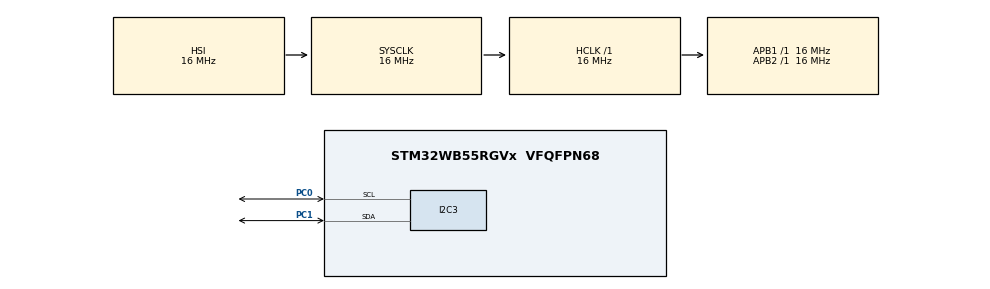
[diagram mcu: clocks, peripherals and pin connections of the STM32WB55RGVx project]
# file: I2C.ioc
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I2C3.Timing=0x00303D5B
Mcu.Family=STM32WB
Mcu.Name=STM32WB55RGVx
Mcu.Package=VFQFPN68
NVIC.PriorityGroup=NVIC_PRIORITYGROUP_4
PC0.GPIO_Pu=GPIO_PULLUP
PC0.GPIO_Speed=GPIO_SPEED_FREQ_HIGH
PC0.Mode=I2C
PC0.Signal=I2C3_SCL
PC1.GPIO_Pu=GPIO_PULLUP
PC1.GPIO_Speed=GPIO_SPEED_FREQ_HIGH
PC1.Mode=I2C
PC1.Signal=I2C3_SDA
ProjectManager.HeapSize=0x200
ProjectManager.StackSize=0x400
ProjectManager.TargetToolchain=STM32CubeIDE
RCC.ADCFreq_Value=64000000
RCC.AHBFreq_Value=16000000
RCC.APB1Freq_Value=16000000
RCC.APB1TimFreq_Value=16000000
RCC.APB2Freq_Value=16000000
RCC.APB2TimFreq_Value=16000000
RCC.APB3Freq_Value=16000000
RCC.CortexFreq_Value=16000000
RCC.HCLKFreq_Value=16000000
RCC.HSE_VALUE=8000000
RCC.HSI48_VALUE=48000000
RCC.HSI_VALUE=16000000
RCC.I2C3CLockSelection=RCC_I2C3CLKSOURCE_HSI
RCC.LSE_VALUE=32768
RCC.PLLSourceVirtual=RCC_PLLSOURCE_HSI
RCC.SYSCLKFreq_VALUE=16000000
RCC.SYSCLKSource=RCC_SYSCLKSOURCE_HSI
RCC.USBFreq_Value=64000000
RCC.VCOOutputFreq_Value=128000000
board=custom

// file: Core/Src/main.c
/* USER CODE BEGIN Header */
/**
  ******************************************************************************
  * @file           : main.c
  * @brief          : Main program body
  ******************************************************************************
  * @attention
  *
  * Copyright (c) 2023 STMicroelectronics.
  * All rights reserved.
  *
  * This software is licensed under terms that can be found in the LICENSE file
  * in the root directory of this software component.
  * If no LICENSE file comes with this software, it is provided AS-IS.
  *
  ******************************************************************************
  */
/* USER CODE END Header */
#include "main.h"

/* USER CODE BEGIN Includes */
#include <string.h>
#include <stdio.h>
#include "MAX17043.h"
/* USER CODE END Includes */

I2C_HandleTypeDef hi2c3;

/* USER CODE BEGIN PV */
float soc;
float volts;
/* USER CODE END PV */

void SystemClock_Config(void);
void PeriphCommonClock_Config(void);
static void MX_GPIO_Init(void);
static void MX_I2C3_Init(void);

int main(void)
{

  /* MCU Configuration--------------------------------------------------------*/

  /* Reset of all peripherals, Initializes the Flash interface and the Systick. */
  HAL_Init();

  /* Configure the system clock */
  SystemClock_Config();

/* Configure the peripherals common clocks */
  PeriphCommonClock_Config();

  /* Initialize all configured peripherals */
  MX_GPIO_Init();
  MX_I2C3_Init();
  /* USER CODE BEGIN 2 */
  MAX17043_Init(&hi2c3);

  /* USER CODE END 2 */

  /* Infinite loop */
  /* USER CODE BEGIN WHILE */
  while (1)
  {
	  soc = MAX17043_ReadSoC(&hi2c3);
	  volts = MAX17043_ReadVoltage(&hi2c3);
	  //HAL_Delay(1000);
    /* USER CODE END WHILE */

  }
}

void SystemClock_Config(void)
{
  RCC_OscInitTypeDef RCC_OscInitStruct = {0};
  RCC_ClkInitTypeDef RCC_ClkInitStruct = {0};

  /** Configure the main internal regulator output voltage
  */
  __HAL_PWR_VOLTAGESCALING_CONFIG(PWR_REGULATOR_VOLTAGE_SCALE1);

  /** Initializes the RCC Oscillators according to the specified parameters
  * in the RCC_OscInitTypeDef structure.
  */
  RCC_OscInitStruct.OscillatorType = RCC_OSCILLATORTYPE_HSI;
  RCC_OscInitStruct.HSIState = RCC_HSI_ON;
  RCC_OscInitStruct.HSICalibrationValue = RCC_HSICALIBRATION_DEFAULT;
  RCC_OscInitStruct.PLL.PLLState = RCC_PLL_NONE;
  if (HAL_RCC_OscConfig(&RCC_OscInitStruct) != HAL_OK)
  {
    Error_Handler();
  }

  /** Configure the SYSCLKSource, HCLK, PCLK1 and PCLK2 clocks dividers
  */
  RCC_ClkInitStruct.ClockType = RCC_CLOCKTYPE_HCLK4|RCC_CLOCKTYPE_HCLK2
                              |RCC_CLOCKTYPE_HCLK|RCC_CLOCKTYPE_SYSCLK
                              |RCC_CLOCKTYPE_PCLK1|RCC_CLOCKTYPE_PCLK2;
  RCC_ClkInitStruct.SYSCLKSource = RCC_SYSCLKSOURCE_HSI;
  RCC_ClkInitStruct.AHBCLKDivider = RCC_SYSCLK_DIV1;
  RCC_ClkInitStruct.APB1CLKDivider = RCC_HCLK_DIV1;
  RCC_ClkInitStruct.APB2CLKDivider = RCC_HCLK_DIV1;
  RCC_ClkInitStruct.AHBCLK2Divider = RCC_SYSCLK_DIV1;
  RCC_ClkInitStruct.AHBCLK4Divider = RCC_SYSCLK_DIV1;

  if (HAL_RCC_ClockConfig(&RCC_ClkInitStruct, FLASH_LATENCY_0) != HAL_OK)
  {
    Error_Handler();
  }
}

void PeriphCommonClock_Config(void)
{
  RCC_PeriphCLKInitTypeDef PeriphClkInitStruct = {0};

  /** Initializes the peripherals clock
  */
  PeriphClkInitStruct.PeriphClockSelection = RCC_PERIPHCLK_SMPS;
  PeriphClkInitStruct.SmpsClockSelection = RCC_SMPSCLKSOURCE_HSI;
  PeriphClkInitStruct.SmpsDivSelection = RCC_SMPSCLKDIV_RANGE1;

  if (HAL_RCCEx_PeriphCLKConfig(&PeriphClkInitStruct) != HAL_OK)
  {
    Error_Handler();
  }
}

static void MX_I2C3_Init(void)
{

  hi2c3.Instance = I2C3;
  hi2c3.Init.Timing = 0x00303D5B;
  hi2c3.Init.OwnAddress1 = 0;
  hi2c3.Init.AddressingMode = I2C_ADDRESSINGMODE_7BIT;
  hi2c3.Init.DualAddressMode = I2C_DUALADDRESS_DISABLE;
  hi2c3.Init.OwnAddress2 = 0;
  hi2c3.Init.OwnAddress2Masks = I2C_OA2_NOMASK;
  hi2c3.Init.GeneralCallMode = I2C_GENERALCALL_DISABLE;
  hi2c3.Init.NoStretchMode = I2C_NOSTRETCH_DISABLE;
  if (HAL_I2C_Init(&hi2c3) != HAL_OK)
  {
    Error_Handler();
  }

  /** Configure Analogue filter
  */
  if (HAL_I2CEx_ConfigAnalogFilter(&hi2c3, I2C_ANALOGFILTER_ENABLE) != HAL_OK)
  {
    Error_Handler();
  }

  /** Configure Digital filter
  */
  if (HAL_I2CEx_ConfigDigitalFilter(&hi2c3, 0) != HAL_OK)
  {
    Error_Handler();
  }

}

static void MX_GPIO_Init(void)
{

  /* GPIO Ports Clock Enable */
  __HAL_RCC_GPIOC_CLK_ENABLE();

}

void Error_Handler(void)
{
  __disable_irq();
  while (1)
  {
  }
}
